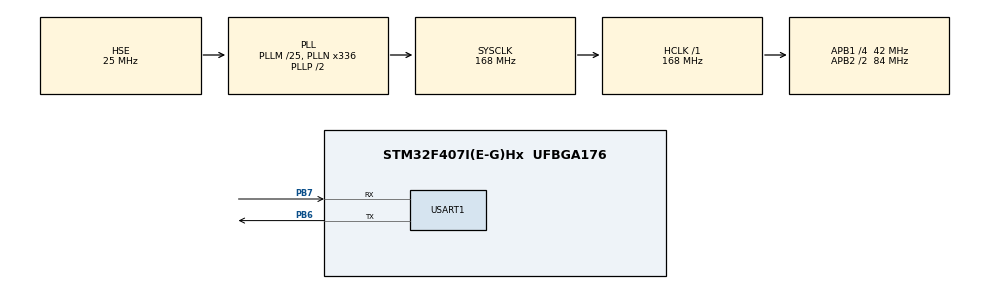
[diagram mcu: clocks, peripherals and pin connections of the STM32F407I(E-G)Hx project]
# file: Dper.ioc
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FREERTOS.Tasks01=defaultTask,0,128,StartDefaultTask,Default,NULL,Dynamic,NULL,NULL
Mcu.Family=STM32F4
Mcu.Name=STM32F407I(E-G)Hx
Mcu.Package=UFBGA176
NVIC.PriorityGroup=NVIC_PRIORITYGROUP_4
NVIC.USART1_IRQn=true\:5\:0\:false\:false\:true\:true\:true\:true\:true
PB6.Mode=Asynchronous
PB6.Signal=USART1_TX
PB7.Mode=Asynchronous
PB7.Signal=USART1_RX
PH0-OSC_IN.Mode=HSE-External-Oscillator
PH0-OSC_IN.Signal=RCC_OSC_IN
PH1-OSC_OUT.Mode=HSE-External-Oscillator
PH1-OSC_OUT.Signal=RCC_OSC_OUT
ProjectManager.HeapSize=0x200
ProjectManager.StackSize=0x400
ProjectManager.TargetToolchain=MDK-ARM V5.27
RCC.48MHZClocksFreq_Value=84000000
RCC.AHBFreq_Value=168000000
RCC.APB1CLKDivider=RCC_HCLK_DIV4
RCC.APB1Freq_Value=42000000
RCC.APB1TimFreq_Value=84000000
RCC.APB2CLKDivider=RCC_HCLK_DIV2
RCC.APB2Freq_Value=84000000
RCC.APB2TimFreq_Value=168000000
RCC.CortexFreq_Value=168000000
RCC.HCLKFreq_Value=168000000
RCC.HSE_VALUE=25000000
RCC.HSI_VALUE=16000000
RCC.LSE_VALUE=32768
RCC.PLLM=25
RCC.PLLN=336
RCC.PLLSourceVirtual=RCC_PLLSOURCE_HSE
RCC.SYSCLKFreq_VALUE=168000000
RCC.SYSCLKSource=RCC_SYSCLKSOURCE_PLLCLK
RCC.VCOOutputFreq_Value=336000000
USART1.VirtualMode=VM_ASYNC
VP_FREERTOS_VS_CMSIS_V1.Mode=CMSIS_V1
board=custom

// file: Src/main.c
/* USER CODE BEGIN Header */
/**
  ******************************************************************************
  * @file           : main.c
  * @brief          : Main program body
  ******************************************************************************
  * @attention
  *
  * Copyright (c) 2025 STMicroelectronics.
  * All rights reserved.
  *
  * This software is licensed under terms that can be found in the LICENSE file
  * in the root directory of this software component.
  * If no LICENSE file comes with this software, it is provided AS-IS.
  *
  ******************************************************************************
  */
/* USER CODE END Header */
#include "main.h"
#include "cmsis_os.h"
#include "usart.h"
#include "gpio.h"

/* USER CODE BEGIN Includes */

#include "sys_core.h" // 引入成员D编写的系统核心头文件

/* USER CODE END Includes */

void SystemClock_Config(void);
void MX_FREERTOS_Init(void);
/* USER CODE BEGIN PFP */
extern void BSP_Sensor_Init(void);   // 成员A
extern void BSP_Actuator_Init(void); // 成员B
extern void BSP_Key_Init(void);      // 成员C
extern void BSP_UART_Init(void);     // 成员C/D
/* USER CODE END PFP */

int main(void)
{

  /* MCU Configuration--------------------------------------------------------*/

  /* Reset of all peripherals, Initializes the Flash interface and the Systick. */
  HAL_Init();

  /* Configure the system clock */
  SystemClock_Config();

  /* Initialize all configured peripherals */
  MX_GPIO_Init();
  MX_USART1_UART_Init();
/* USER CODE BEGIN 2 */

  // 1. 初始化各成员的硬件 (BSP Layer)
  BSP_UART_Init();      // 成员 D (通信)
  BSP_Actuator_Init();  // <--- 补上这一行！成员 B (执行器: 风扇/LED等)
  BSP_Sensor_Init();
  // (后续拿到成员 A 和 C 的代码后，也要在这里分别调用 BSP_Sensor_Init 和 BSP_Key_Init)

  // 2. 创建 FreeRTOS 资源 (App Layer)
  RTOS_Structure_Init();

  /* USER CODE END 2 */

  /* Call init function for freertos objects (in cmsis_os2.c) */
  MX_FREERTOS_Init();

  /* Start scheduler */
  osKernelStart();

  /* We should never get here as control is now taken by the scheduler */

  /* Infinite loop */
  while (1)
  {

  }
}

void SystemClock_Config(void)
{
  RCC_OscInitTypeDef RCC_OscInitStruct = {0};
  RCC_ClkInitTypeDef RCC_ClkInitStruct = {0};

  /** Configure the main internal regulator output voltage
  */
  __HAL_RCC_PWR_CLK_ENABLE();
  __HAL_PWR_VOLTAGESCALING_CONFIG(PWR_REGULATOR_VOLTAGE_SCALE1);

  /** Initializes the RCC Oscillators according to the specified parameters
  * in the RCC_OscInitTypeDef structure.
  */
  RCC_OscInitStruct.OscillatorType = RCC_OSCILLATORTYPE_HSE;
  RCC_OscInitStruct.HSEState = RCC_HSE_ON;
  RCC_OscInitStruct.PLL.PLLState = RCC_PLL_ON;
  RCC_OscInitStruct.PLL.PLLSource = RCC_PLLSOURCE_HSE;
  RCC_OscInitStruct.PLL.PLLM = 25;
  RCC_OscInitStruct.PLL.PLLN = 336;
  RCC_OscInitStruct.PLL.PLLP = RCC_PLLP_DIV2;
  RCC_OscInitStruct.PLL.PLLQ = 4;
  if (HAL_RCC_OscConfig(&RCC_OscInitStruct) != HAL_OK)
  {
    Error_Handler();
  }

  /** Initializes the CPU, AHB and APB buses clocks
  */
  RCC_ClkInitStruct.ClockType = RCC_CLOCKTYPE_HCLK|RCC_CLOCKTYPE_SYSCLK
                              |RCC_CLOCKTYPE_PCLK1|RCC_CLOCKTYPE_PCLK2;
  RCC_ClkInitStruct.SYSCLKSource = RCC_SYSCLKSOURCE_PLLCLK;
  RCC_ClkInitStruct.AHBCLKDivider = RCC_SYSCLK_DIV1;
  RCC_ClkInitStruct.APB1CLKDivider = RCC_HCLK_DIV4;
  RCC_ClkInitStruct.APB2CLKDivider = RCC_HCLK_DIV2;

  if (HAL_RCC_ClockConfig(&RCC_ClkInitStruct, FLASH_LATENCY_5) != HAL_OK)
  {
    Error_Handler();
  }
}

void Error_Handler(void)
{
  __disable_irq();
  while (1)
  {
  }
}
